# PIC32CX2051BZ62132 register map
Vendor: Microchip Technology; Series: PIC32CXBZ62; File version: 0
CPU: CM4 r0p1, little endian, MPU, FPU, 3 interrupt priority bits, 58 interrupts
Registers are 32-bit, read-write, reset 0x0 unless marked. A register's access mark holds for its fields unless they carry their own. Offsets are from the block's base; [hi:lo] are bit positions; {n}, {i} and the like mark numbered series.

## ROT — Secure Root of Trust Macro
Base 0x44003000
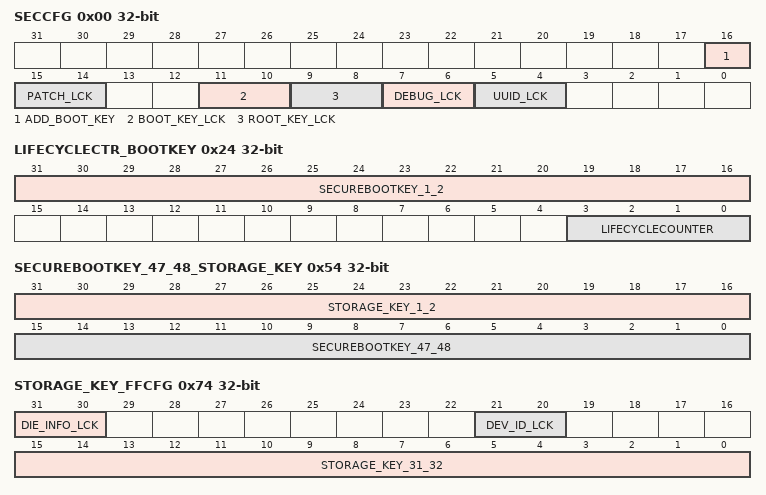
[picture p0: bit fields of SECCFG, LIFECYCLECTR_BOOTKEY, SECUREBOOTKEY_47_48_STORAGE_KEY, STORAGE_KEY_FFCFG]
0x00 SECCFG — Secure Configuration HOLDING REGISTER1,2
  [16] ADD_BOOT_KEY — Additional boot Key bit
  [15:14] PATCH_LCK — Lock bits for patch
    0=Patch config and code are not locked; 1=Patch config and code are locked and cannot be programmed; 2=Patch config and code are locked and cannot be programmed; 3=Patch config and code are locked and cannot be programmed
  [11:10] BOOT_KEY_LCK — Lock bits for Secure Boot/OTA Key
    0=Secure boot key is not locked; 1=Secure boot key is locked and cannot be programmed; 2=Secure boot key is locked and cannot be programmed; 3=Secure boot key is locked and cannot be programmed
  [9:8] ROOT_KEY_LCK — Lock bits for storage root Key
    0=Storage root key is not locked; 1=Storage root key is locked and cannot be programmed; 2=Storage root key is locked and cannot be programmed; 3=Storage root key is locked and cannot be programmed
  [7:6] DEBUG_LCK — Lock bits for debug/programming
    0=Debug is not locked; 1=Debug is locked; 2=Debug is locked; 3=Debug is locked
  [5:4] UUID_LCK — Programming lock bits for Unique ID fuses
    0=Unique ID is not locked; 1=Unique ID is locked and cannot be programmed; 2=Unique ID is locked and cannot be programmed; 3=Unique ID is locked and cannot be programmed
{0x4+4i} ANTIROLLBACKCOUNTER[{i}] (i=0..7)
  [7:0] ANTIROLLBACKCOUNTER — Anti rollback counter bits
0x24 LIFECYCLECTR_BOOTKEY — Life cycle counter and Secure boot key LSB bytes
  [31:16] SECUREBOOTKEY_1_2 — Secure boot key bits
  [3:0] LIFECYCLECOUNTER — Life cycle counter bits
{0x28+4i} SECUREBOOTKEY_3_46[{i}] (i=0..10) — Secure boot key
  [31:0] SECUREBOOTKEY_3_46 — Secure boot key bits
0x54 SECUREBOOTKEY_47_48_STORAGE_KEY — Secure boot key, Storage Key
  [31:16] STORAGE_KEY_1_2 — Storage root key bits
  [15:0] SECUREBOOTKEY_47_48 — Secure boot key bits
{0x58+4i} STORAGE_KEY_3_30[{i}] (i=0..6) — Storage Key
  [31:0] STORAGE_KEY_3_30 — Storage Key bits
0x74 STORAGE_KEY_FFCFG
  [31:30] DIE_INFO_LCK — Die info bits
    0=Die information fuses are not locked; 1=Die information fuses are locked and cannot be programmed; 2=Die information fuses are locked and cannot be programmed; 3=Die information fuses are locked and cannot be programmed
  [21:20] DEV_ID_LCK — Device ID bits
    0=Device ID fuses are not locked; 1=Device ID fuses are locked and cannot be programmed; 2=Device ID fuses are locked and cannot be programmed; 3=Device ID fuses are locked and cannot be programmed
  [15:0] STORAGE_KEY_31_32 — Storage Key bits
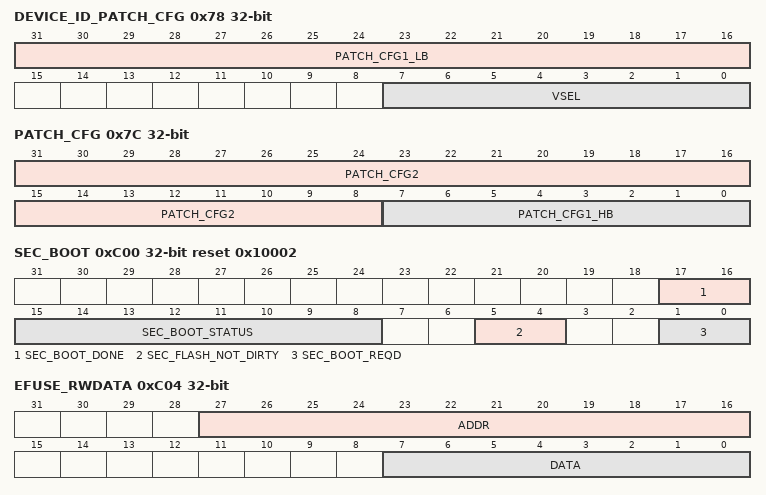
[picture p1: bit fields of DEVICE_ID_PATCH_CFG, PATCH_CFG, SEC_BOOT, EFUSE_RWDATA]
0x78 DEVICE_ID_PATCH_CFG — Device ID and Patch CFG
  [31:16] PATCH_CFG1_LB — Patch CFG-1 lower 16 bits
  [7:0] VSEL — VSEL of device ID
0x7C PATCH_CFG
  [31:8] PATCH_CFG2 — Patch CFG-2 bits
  [7:0] PATCH_CFG1_HB — Patch CFG-1 higher 8 bits
{0x80+4i} PATCH_CODE[{i}] (i=0..59)
  [31:0] PATCH_CODE — Patch Code bits
{0x170+4i} UUID[{i}] (i=0..3) — Unique ID
  [31:0] UUID — Unique ID bits
0xC00 SEC_BOOT reset 0x10002 — Secure Boot Register
  [17:16] SEC_BOOT_DONE — Bits to indicate that secure boot is done
    0=S ecure boot is done; 1=S ecure boot is not done; 2=S ecure boot is not done; 3=S ecure boot is done
  [15:8] SEC_BOOT_STATUS — Bits to indicate that secure boot status
  [5:4] SEC_FLASH_NOT_DIRTY — Bits to indicate whether the Flash contents have been changed since the last code authentication operation
    0=Flash contents have changed since the last authentication; 1=Flash contents have changed since the last authentication; 2=Flash contents have changed since the last authentication; 3=Flash contents have not changed since the last authentication
  [1:0] SEC_BOOT_REQD — Bits to indicate that secure boot is required on the next device reset.
    0=S ecure boot code authentication is required; 1=S ecure boot code authentication is NOT required; 2=S ecure boot code authentication is NOT required; 3=S ecure boot code authentication is required
0xC04 EFUSE_RWDATA
  [27:16] ADDR — eFuse Program/Read Address
  [7:0] DATA — eFuse Program (Write) Data
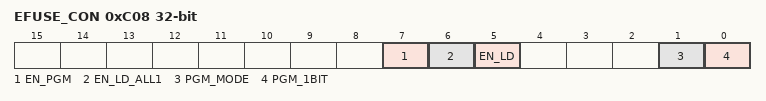
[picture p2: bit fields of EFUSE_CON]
0xC08 EFUSE_CON — Efuse Configuration Register2
  [7] EN_PGM — eFuse Programming Start bit
    0=EFuse Programming operation has completed; 1=Start eFuse Programming operation
  [6] EN_LD_ALL1 — eFuse Panel Read Start bit for loading into the holding registers
    0=EFuse Read operation has completed; 1=Start eFuse Read operation for entire eFuse panel
  [5] EN_LD — eFuse Word Read Start bit for loading the fuse byte pointed by ADDR field into the holding register
    0=EFuse Read operation has completed; 1=Start eFuse Read operation for specified eFuse word as addressed in EFUSE_RWDATA register
  [1] PGM_MODE — eFuse Programming Mode Enable bit
    0=EFuse Programming disabled; 1=EFuse Programming enabled
  [0] PGM_1BIT — eFuse CTRL to program 1 bit at a time. Valid only when EN_PGM is set
    0=EFuse controller will program EFUSE_RWDATA.DATA[15:0] to the address in EFUSE_RWDATA.ADDR[11:3]; 1=EFuse controller will program EFUSE_RWDATA.DATA[0] to the address in EFUSE_RWDATA.ADDR[11:0]
